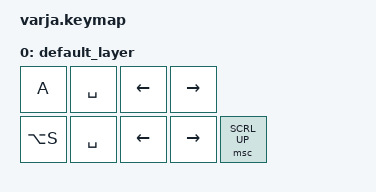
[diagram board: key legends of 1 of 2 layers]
#include <behaviors.dtsi>
#include <dt-bindings/zmk/bt.h>
#include <dt-bindings/zmk/keys.h>
#include <dt-bindings/zmk/pointing.h>

/ {
    keymap {
        compatible = "zmk,keymap";

        default_layer {
            bindings = <
&kp A      &kp SPACE  &kp LEFT_ARROW  &kp RIGHT_ARROW
&kp LA(S)  &kp SPACE  &kp LEFT_ARROW  &kp RIGHT_ARROW  &msc SCRL_UP
            >;
        };

        bt_layer {
            bindings = <
&bootloader   &none         &none         &BT_CLR
&bt BT_SEL 3  &bt BT_SEL 2  &bt BT_SEL 1  &bt BT_SEL 0
            >;
        };
    };
};
